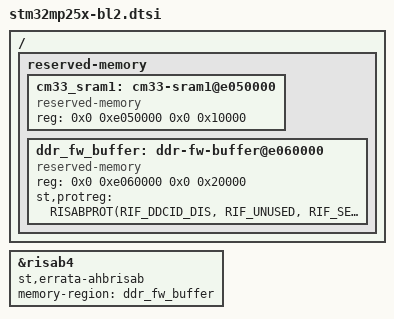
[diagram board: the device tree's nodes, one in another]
// SPDX-License-Identifier: (GPL-2.0-only OR BSD-3-Clause)
/*
 * Copyright (C) STMicroelectronics 2024 - All Rights Reserved
 * Author: Loic Pallardy loic.pallardy@foss.st.com for STMicroelectronics.
 */

/*
 * stm32mp257f reserved memory device tree configuration
 * Project : ostl
 * Generated by XLmx tool version 2.7 - 12/2/2024 11:20:00 AM
 */

/ {
	reserved-memory {
		#address-cells = <2>;
		#size-cells = <2>;
		ranges;

		cm33_sram1: cm33-sram1@e050000 {
			compatible = "reserved-memory";
			reg = <0x0 0xe050000 0x0 0x10000>;
			#memory-region-cells = <0>;
		};

		ddr_fw_buffer: ddr-fw-buffer@e060000 {
			compatible = "reserved-memory";
			reg = <0x0 0xe060000 0x0 0x20000>;
			#memory-region-cells = <0>;
			st,protreg = <RISABPROT(RIF_DDCID_DIS, RIF_UNUSED, RIF_SEC, RIF_PRIV, RIF_CFEN, RIF_CID2_BF, RIF_CID2_BF, RIF_UNUSED)>;
		};
	};
};

&risab4 {
	st,errata-ahbrisab;
	memory-region = <&ddr_fw_buffer>;
	status = "okay";
};
